# DA14580 register map
Vendor: Dialog; Series: DA14580x; File version: 1.2
CPU: CM0 r1p0, little endian, MPU, FPU, 3 interrupt priority bits
Registers are 16-bit, read-write, reset 0x0 unless marked. A register's access mark holds for its fields unless they carry their own. Offsets are from the block's base; [hi:lo] are bit positions.

## adc580_bif_nl01 — adc580_bif_nl01 registers
Base 0x50001500
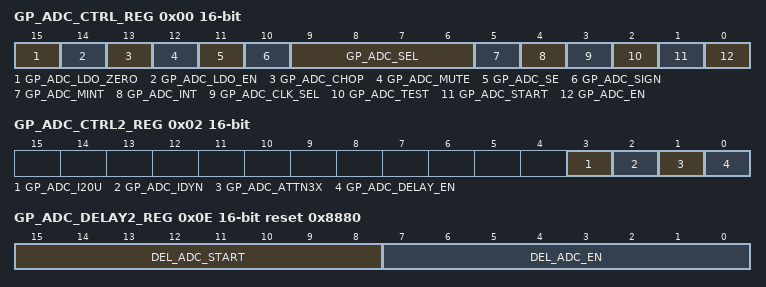
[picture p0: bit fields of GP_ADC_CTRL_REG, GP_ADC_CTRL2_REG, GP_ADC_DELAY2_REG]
0x00 GP_ADC_CTRL_REG — General Purpose ADC Control Register
  [15] GP_ADC_LDO_ZERO — Forces LDO-output to 0V.
  [14] GP_ADC_LDO_EN — Turns on LDO.
  [13] GP_ADC_CHOP — Takes two samples with opposite GP_ADC_SIGN to cancel the internal offset voltage of the ADC; Highly recommended for DC-measurements.
  [12] GP_ADC_MUTE — Takes sample at mid-scale (to dertermine the internal offset and/or noise of the ADC with regards to VDD_REF which is also sampled by the ADC).
  [11] GP_ADC_SE — 0 = Differential mode 1 = Single ended mode
  [10] GP_ADC_SIGN — 0 = Default 1 = Conversion with opposite sign at input and output to cancel out the internal offset of the ADC and low-frequency
  [9:6] GP_ADC_SEL — ADC input selection which must be set before the GP_ADC_START bit is enabled. If GP_ADC_SE = 1 (single ended mode): 0000 = P0[0] 0001 = P0[1] 0010 = P0[2] 0011 = P0[3] 0100 = AVS 0101 = VDD_REF 0110 = VDD_RTT (=VDD_REF) 0111 = VBAT3V 1000 = VDCDC 1001 = VBAT1V All other combinations are reserved. If GP_ADC_SE = 0 (differential mode): 0000 = P0[0] vs P0[1] All other combinations are P0[2] vs P0[3].
  [5] GP_ADC_MINT — 0 = Disable (mask) GP_ADC_INT. 1 = Enable GP_ADC_INT to ICU.
  [4] GP_ADC_INT ro — 1 = AD conversion ready and has generated an interrupt. Must be cleared by writing any value to GP_ADC_CLEAR_INT_REG.
  [3] GP_ADC_CLK_SEL — 0 = Internal high-speed ADC clock used. 1 = Digital clock used.
  [2] GP_ADC_TEST — Reserved, keep 0.
  [1] GP_ADC_START — 0 = ADC conversion ready. 1 = If a 1 is written, the ADC starts a conversion. After the conversion this bit will be set to 0 and the GP_ADC_INT bit will be set.
  [0] GP_ADC_EN — 0 = ADC is disabled and in reset. 1 = ADC is enabled and sampling of input is started.
0x02 GP_ADC_CTRL2_REG — General Purpose ADC Second Control Register
  [3] GP_ADC_I20U — Adds 20uA constant load current at the ADC LDO to minimize ripple on the reference voltage of the ADC.
  [2] GP_ADC_IDYN — Enables dynamic load current at the ADC LDO to minimize ripple on the reference voltage of the ADC.
  [1] GP_ADC_ATTN3X — 0 = Input voltages up to 1.2V allowed. 1 = Input voltages up to 3.6V allowed by enabling 3x attenuator.
  [0] GP_ADC_DELAY_EN — Enables delay function for several signals. This is not auto-cleared. Toggle this bit before every sampling to enable succesive conversions.
0x04 GP_ADC_OFFP_REG reset 0x200 — General Purpose ADC Positive Offset Register
  [9:0] GP_ADC_OFFP — Offset adjust of 'positive' array of ADC-network (effective if 'GP_ADC_SE=0', or 'GP_ADC_SE=1 AND GP_ADC_SIGN=0')
0x06 GP_ADC_OFFN_REG reset 0x200 — General Purpose ADC Negative Offset Register
  [9:0] GP_ADC_OFFN — Offset adjust of 'negative' array of ADC-network (effective if 'GP_ADC_SE=0', or 'GP_ADC_SE=1 AND GP_ADC_SIGN=1')
0x08 GP_ADC_CLEAR_INT_REG — General Purpose ADC Clear Interrupt Register
  [15:0] GP_ADC_CLR_INT wo — Writing any value to this register will clear the ADC_INT interrupt. Reading returns 0.
0x0A GP_ADC_RESULT_REG — General Purpose ADC Result Register
  [9:0] GP_ADC_VAL ro — Returns the 10 bits linear value of the last AD conversion.
0x0C GP_ADC_DELAY_REG — General Purpose ADC Delay Register
  [7:0] DEL_LDO_EN — Defines the delay before the LDO enable (GP_ADC_LDO_EN). Reset value is 0 µs since the LDO enable should be the first thing to be programmed in the sequence of bringing the GP ADC up.
0x0E GP_ADC_DELAY2_REG reset 0x8880 — General Purpose ADC Second Delay Register
  [15:8] DEL_ADC_START — Defines the delay for the GP_ADC_START bit. Reset value is 17 µs which is the recommended value to wait before starting the GP ADC. This is the third and last step of bringing up the GP ADC
  [7:0] DEL_ADC_EN — Defines the delay for the GP_ADC_EN bit. Reset value is 16 µs which is the recommended value to wait after enabling the LDO. This is the second step in bringing up the GP ADC.
